# PIC32MK0512MCF100 device description
Architecture: MIPS; Family: PIC32MK; Series: PIC32MK
Registers are 32-bit, read-write, no defined reset value unless marked. A register's access mark holds for its fields unless they carry their own. Offsets are from the block's base; [hi:lo] are bit positions; 'fields as' and 'values as' point back to an identical list.

## CDAC
Instances: CDAC 0x1f82c200 in periph_pb2_std
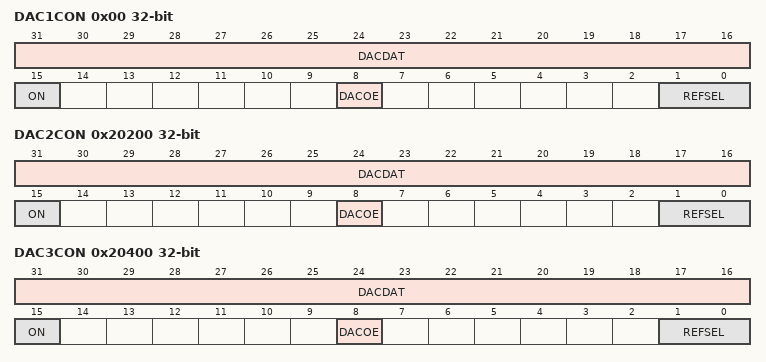
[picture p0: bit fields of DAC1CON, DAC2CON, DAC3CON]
0x00 DAC1CON — CDAC Control Register
  [31:16] DACDAT
  [15] ON — CDAC Enable bit
    1=The CDAC is enabled; 0=The CDAC is disabled
  [8] DACOE — CDAC Output Buffer Enable bit
    1=Output is enabled; CDAC voltage is connected to the pin; 0=Output is disabled; drive to pin is floating
  [1:0] REFSEL — Reference Source Select bits
    3=Positive reference voltage = AVDD; 2=No reference selected (no reference current consumption); 1=No reference selected (no reference current consumption); 0=No reference selected (no reference current consumption)
0x20200 DAC2CON — CDAC Control Register
  fields as DAC1CON
0x20400 DAC3CON — CDAC Control Register
  fields as DAC1CON

## RCON
Instances: RCON 0x1f801200 in periph_pb1_std
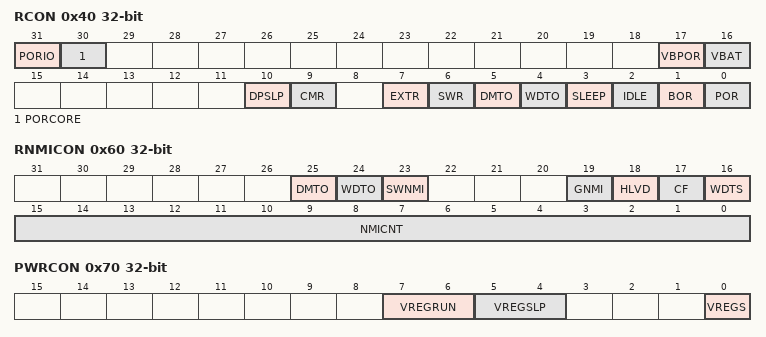
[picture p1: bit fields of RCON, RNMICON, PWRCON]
0x40 RCON — Reset Control Register
  [31] PORIO — I/O Voltage POR Flag bit
    1=A Power-up Reset has occurred due to I/O Voltage; 0=A Power-up Reset has not occurred due to I/O Voltage
  [30] PORCORE — Core Voltage POR Flag bit
    1=A Power-up Reset has occurred due to Core Voltage; 0=A Power-up Reset has not occurred due to Core Voltage
  [17] VBPOR — VBPOR Mode Flag bit
    1=A VBAT domain POR has occurred; 0=A VBAT domain POR has not occurred
  [16] VBAT — VBAT Mode Flag bit
    1=A POR exit from VBAT has occurred (a true POR must be established with the valid VBAT voltage on the VBAT pin); 0=A POR exit from VBAT has not occurred
  [10] DPSLP — Deep Sleep Mode Flag bit
    1=Deep Sleep mode has occurred; 0=Deep Sleep mode has not occurred
  [9] CMR — Configuration Mismatch Reset Flag bit
    1=A Configuration Mismatch Reset has occurred; 0=A Configuration Mismatch Reset has not occurred
  [7] EXTR — External Reset (MCLR) Pin Flag bit
    1=Master Clear (pin) Reset has occurred; 0=Master Clear (pin) Reset has not occurred
  [6] SWR — Software Reset Flag bit
    1=Software Reset was executed; 0=Software Reset was not executed
  [5] DMTO — Deadman Timer Time-out Flag bit
    1=A DMT time-out has occurred; 0=A DMT time-out has not occurred
  [4] WDTO — Watchdog Timer Time-out Flag bit
    1=WDT Time-out has occurred; 0=WDT Time-out has not occurred
  [3] SLEEP — Wake From Sleep Flag bit
    1=Device was in Sleep mode; 0=Device was not in Sleep mode
  [2] IDLE — Wake From Idle Flag bit
    1=Device was in Idle mode; 0=Device was not in Idle mode
  [1] BOR — Brown-out Reset Flag bit
    1=Brown-out Reset has occurred; 0=Brown-out Reset has not occurred
  [0] POR — Power-on Reset Flag bit
    1=Power-on Reset has occurred; 0=Power-on Reset has not occurred
0x50 RSWRST wo — Software Reset Register
  [0] SWRST — Software Reset Trigger bit
    1=Enable software Reset event; 0=No effect
0x60 RNMICON — Non-Maskable Interrupt (NMI) Control Register
  [25] DMTO — Deadman Timer Time-out Flag bit
    1=DMT time-out has occurred and caused a NMI; 0=DMT time-out has not occurred
  [24] WDTO — Watchdog Timer Time-Out Flag bit
    1=WDT time-out has occurred and caused a NMI; 0=WDT time-out has not occurred
  [23] SWNMI — Software NMI Trigger.
    1=An NMI will be generated; 0=An NMI will not be generated
  [19] GNMI — General NMI bit
    1=A general NMI event has been detected or a user-initiated NMI event has occurred; 0=A general NMI event has not been detected
  [18] HLVD
  [17] CF — Clock Fail Detect bit
    1=FSCM has detected clock failure and caused an NMI; 0=FSCM has not detected clock failure
  [16] WDTS — Watchdog Timer Time-out in Sleep Mode Flag bit (Setting this bit will cause a WDT NMI)
    1=WDT time-out has occurred during Sleep mode and caused a wake-up from sleep; 0=WDT time-out has not occurred during Sleep mode
  [15:0] NMICNT — NMI Reset Counter Value bits
    255=255 SYSCLK cycles before a device Reset occurs; 254=254 SYSCLK cycles before a device Reset occurs; 1=1 SYSCLK cycle before a device Reset occurs; 0=No delay between NMI assertion and device Reset event
0x70 PWRCON — Power Control Register
  [7:6] VREGRUN
  [5:4] VREGSLP
  [0] VREGS — Internal Voltage Regulator Stand-by Enable bit
    1=Voltage regulator will remain active during Sleep; 0=Voltage regulator will go to Stand-by mode during Sleep

## Notices in the file
Copyright (c) 2017 Microchip Technology Inc.
SPDX-License-Identifier: Apache-2.0
Licensed under the Apache License, Version 2.0 (the "License");
you may not use this file except in compliance with the License.
You may obtain a copy of the License at
http://www.apache.org/licenses/LICENSE-2.0
Unless required by applicable law or agreed to in writing, software
distributed under the License is distributed on an "AS IS" BASIS,
WITHOUT WARRANTIES OR CONDITIONS OF ANY KIND, either express or implied.
See the License for the specific language governing permissions and
limitations under the License.
